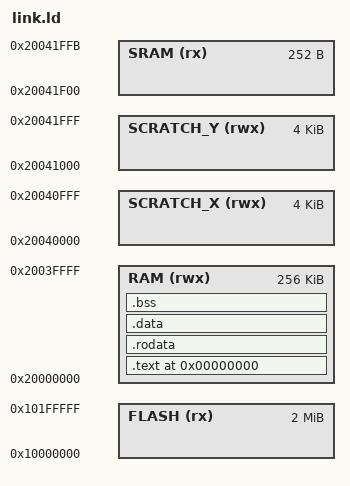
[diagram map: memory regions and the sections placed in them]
ENTRY(_start)

MEMORY
{
    FLASH(rx) : ORIGIN = 0x10000000, LENGTH = 2048k
    RAM(rwx) : ORIGIN = 0x20000000, LENGTH = 256k
    SRAM(rx) : ORIGIN = 0x20041f00, LENGTH = 252
    SCRATCH_X(rwx) : ORIGIN = 0x20040000, LENGTH = 4k
    SCRATCH_Y(rwx) : ORIGIN = 0x20041000, LENGTH = 4k
}

SECTIONS
{
    . = 0x0;
    __start = .;
    __text_start = .;
    .text :
    {
        *(.text)
    } > RAM
    . = ALIGN(4096);
    __text_end = .;
 
    __rodata_start = .;
    .rodata :
    {
        *(.rodata)
    } > RAM
    . = ALIGN(4096);
    __rodata_end = .;
 
    __data_start = .;
    .data :
    {
        *(.data)
    } > RAM
    . = ALIGN(4096);
    __data_end = .;
 
    __bss_start = .;
    .bss :
    {
        bss = .;
        *(.bss)
    } > RAM
    . = ALIGN(4096);
    __bss_end = .;
    __bss_size = __bss_end - __bss_start;
    __end = .;
}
